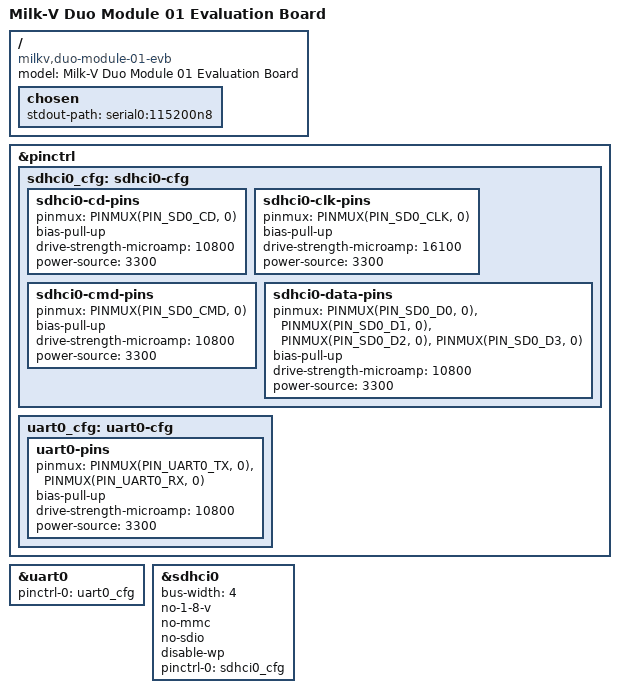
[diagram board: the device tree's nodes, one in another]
// SPDX-License-Identifier: (GPL-2.0 OR MIT)

/dts-v1/;

#include "sg2000-milkv-duo-module-01.dtsi"

/ {
	model = "Milk-V Duo Module 01 Evaluation Board";
	compatible = "milkv,duo-module-01-evb", "milkv,duo-module-01", "sophgo,sg2000";

	chosen {
		stdout-path = "serial0:115200n8";
	};
};

&pinctrl {
	sdhci0_cfg: sdhci0-cfg {
		sdhci0-cd-pins {
			pinmux = <PINMUX(PIN_SD0_CD, 0)>;
			bias-pull-up;
			drive-strength-microamp = <10800>;
			power-source = <3300>;
		};

		sdhci0-clk-pins {
			pinmux = <PINMUX(PIN_SD0_CLK, 0)>;
			bias-pull-up;
			drive-strength-microamp = <16100>;
			power-source = <3300>;
		};

		sdhci0-cmd-pins {
			pinmux = <PINMUX(PIN_SD0_CMD, 0)>;
			bias-pull-up;
			drive-strength-microamp = <10800>;
			power-source = <3300>;
		};

		sdhci0-data-pins {
			pinmux = <PINMUX(PIN_SD0_D0, 0)>,
				 <PINMUX(PIN_SD0_D1, 0)>,
				 <PINMUX(PIN_SD0_D2, 0)>,
				 <PINMUX(PIN_SD0_D3, 0)>;
			bias-pull-up;
			drive-strength-microamp = <10800>;
			power-source = <3300>;
		};
	};

	uart0_cfg: uart0-cfg {
		uart0-pins {
			pinmux = <PINMUX(PIN_UART0_TX, 0)>,
				 <PINMUX(PIN_UART0_RX, 0)>;
			bias-pull-up;
			drive-strength-microamp = <10800>;
			power-source = <3300>;
		};
	};
};

&uart0 {
	pinctrl-0 = <&uart0_cfg>;
	pinctrl-names = "default";
	status = "okay";
};

&sdhci0 {
	bus-width = <4>;
	no-1-8-v;
	no-mmc;
	no-sdio;
	disable-wp;
	pinctrl-0 = <&sdhci0_cfg>;
	pinctrl-names = "default";
	status = "okay";
};
